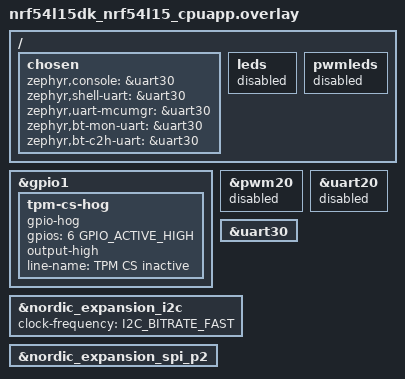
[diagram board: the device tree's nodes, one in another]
/*
 * Copyright (c) 2025 Sensry GmbH
 * SPDX-License-Identifier: Apache-2.0
 */

/ {
	chosen {
		zephyr,console = &uart30;
		zephyr,shell-uart = &uart30;
		zephyr,uart-mcumgr = &uart30;
		zephyr,bt-mon-uart = &uart30;
		zephyr,bt-c2h-uart = &uart30;
	};

	/* DK LEDs share SPI MISO (P2.09) and chip-select pins (P1.10/P1.14). */
	leds {
		status = "disabled";
	};

	/* The DK PWM LED also uses the BMI270 chip-select pin P1.10. */
	pwmleds {
		status = "disabled";
	};
};

/*
 * Keep the unused TPM chip select inactive with a GPIO hog. Without this, the
 * unselected TPM drives the shared SPI MISO line and the shield sensors fail
 * to probe.
 */
&gpio1 {
	tpm-cs-hog {
		gpio-hog;
		gpios = <6 GPIO_ACTIVE_HIGH>;
		output-high;
		line-name = "TPM CS inactive";
	};
};

/* PWM20 defaults to P1.10, which the shield uses for BMI270 chip select. */
&pwm20 {
	status = "disabled";
};

/* P1.04/P1.05 belong to PDM; use the DK's VCOM0 console. */
&uart20 {
	status = "disabled";
};

&uart30 {
	status = "okay";
};

/*
 * The shield wires SPI to the P2 header (P2.06/P2.08/P2.09). On the nRF54L15,
 * SPIM22 can only use P1 pins; P2 routing is available on SPIM20/SPIM21 and
 * only in constant-latency mode. Use SPI21 and leave the DK's SPI22
 * configuration on the P1 header untouched.
 */
&nordic_expansion_i2c {
	clock-frequency = <I2C_BITRATE_FAST>;
	status = "okay";
};

&nordic_expansion_spi_p2 {
	status = "okay";
};
